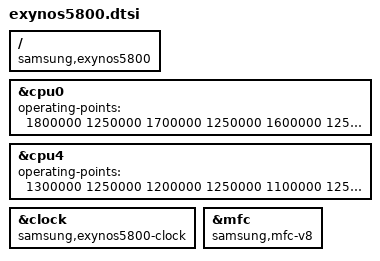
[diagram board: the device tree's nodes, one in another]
/*
 * SAMSUNG EXYNOS5800 SoC device tree source
 *
 * Copyright (c) 2014 Samsung Electronics Co., Ltd.
 *		http://www.samsung.com
 *
 * SAMSUNG EXYNOS5800 SoC device nodes are listed in this file.
 * EXYNOS5800 based board files can include this file and provide
 * values for board specfic bindings.
 *
 * This program is free software; you can redistribute it and/or modify
 * it under the terms of the GNU General Public License version 2 as
 * published by the Free Software Foundation.
 */

#include "exynos5420.dtsi"

/ {
	compatible = "samsung,exynos5800", "samsung,exynos5";
};

&cpu0 {
	operating-points = <
		1800000 1250000
		1700000 1250000
		1600000 1250000
		1500000 1100000
		1400000 1100000
		1300000 1100000
		1200000 1000000
		1100000 1000000
		1000000 1000000
		 900000 1000000
		 800000  900000
		 700000  900000
		 600000  900000
		 500000  900000
		 400000  900000
		 300000  900000
		 200000  900000
	>;
};

&cpu4 {
	operating-points = <
		1300000 1250000
		1200000 1250000
		1100000 1250000
		1000000 1100000
		 900000 1100000
		 800000 1100000
		 700000 1000000
		 600000 1000000
		 500000 1000000
		 400000 1000000
		 300000  900000
		 200000  900000
	>;
};

&clock {
	compatible = "samsung,exynos5800-clock";
};

&mfc {
	compatible = "samsung,mfc-v8";
};
